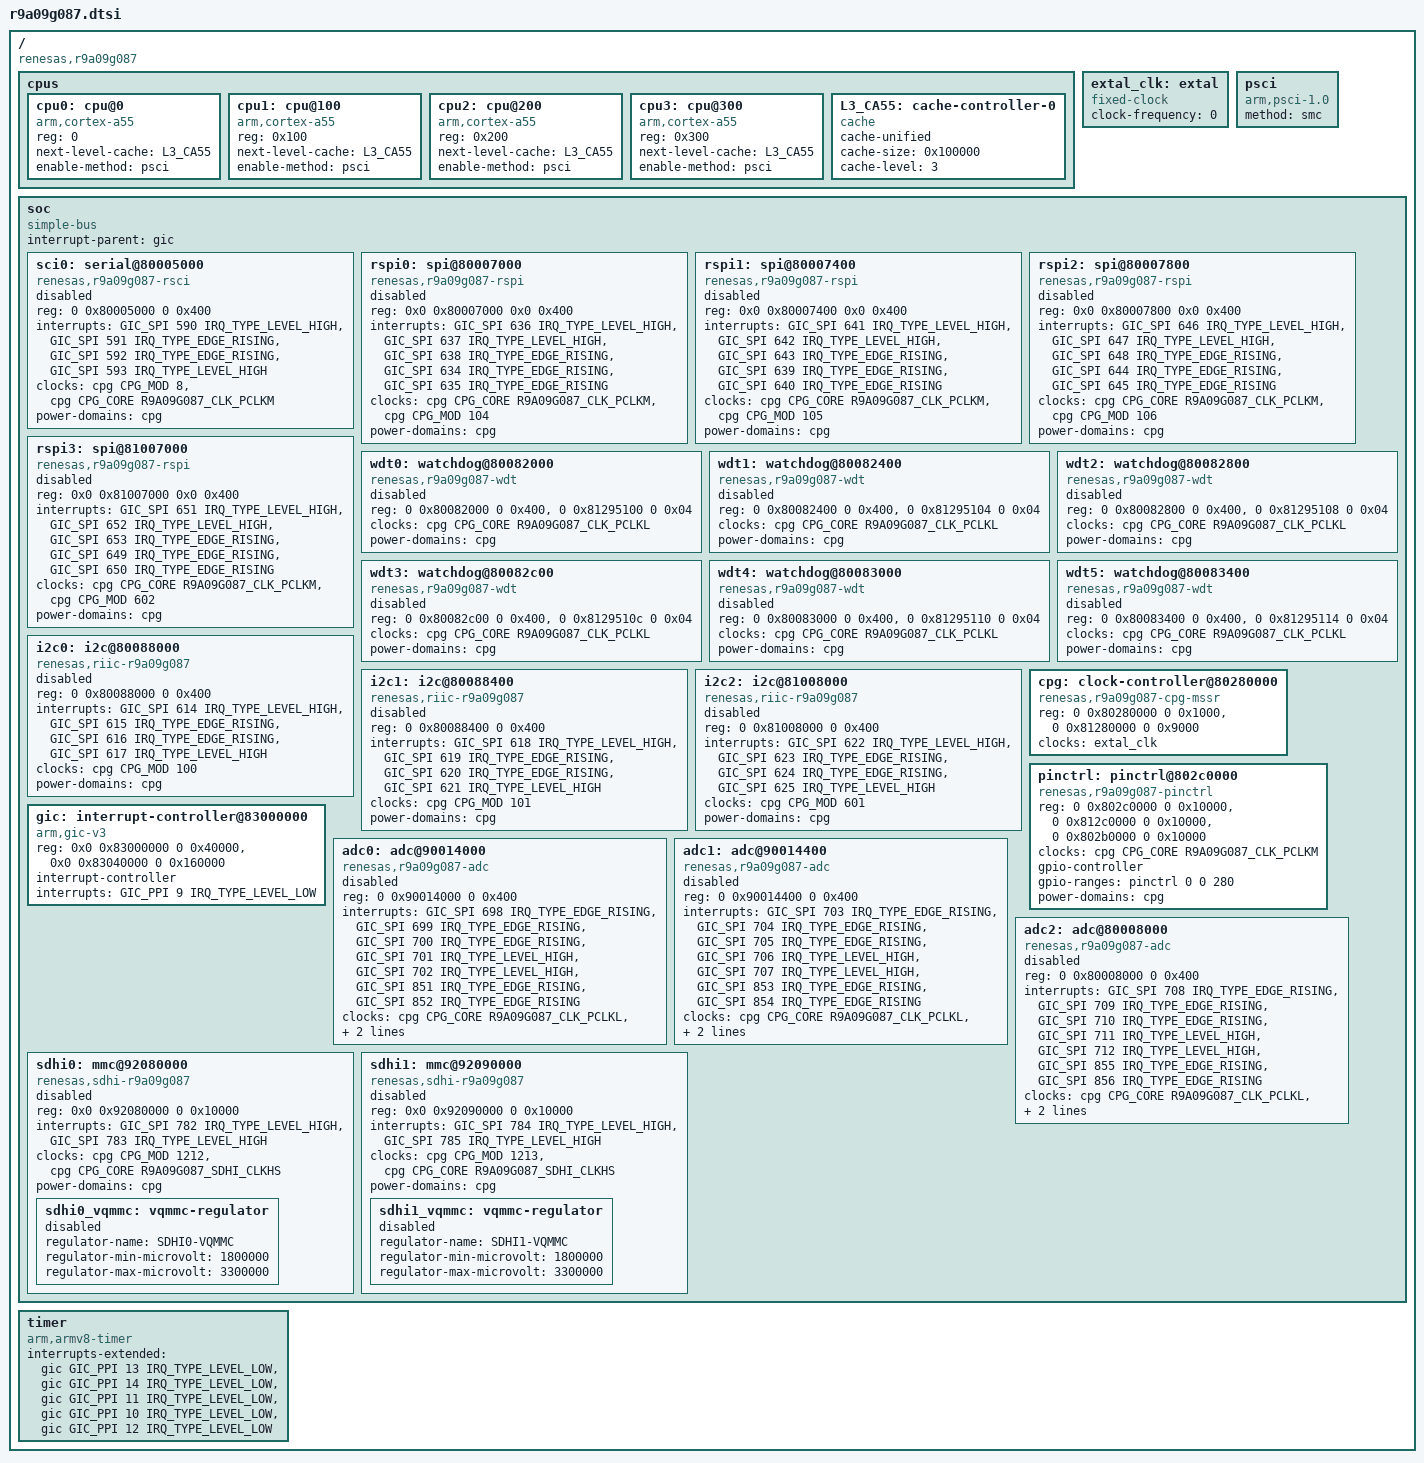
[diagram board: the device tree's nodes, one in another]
// SPDX-License-Identifier: (GPL-2.0-only OR BSD-2-Clause)
/*
 * Device Tree Source for the RZ/N2H SoC
 *
 * Copyright (C) 2025 Renesas Electronics Corp.
 */

#include <dt-bindings/clock/renesas,r9a09g087-cpg-mssr.h>
#include <dt-bindings/interrupt-controller/arm-gic.h>

/ {
	compatible = "renesas,r9a09g087";
	#address-cells = <2>;
	#size-cells = <2>;

	cpus {
		#address-cells = <1>;
		#size-cells = <0>;

		cpu0: cpu@0 {
			compatible = "arm,cortex-a55";
			reg = <0>;
			device_type = "cpu";
			next-level-cache = <&L3_CA55>;
			enable-method = "psci";
		};

		cpu1: cpu@100 {
			compatible = "arm,cortex-a55";
			reg = <0x100>;
			device_type = "cpu";
			next-level-cache = <&L3_CA55>;
			enable-method = "psci";
		};

		cpu2: cpu@200 {
			compatible = "arm,cortex-a55";
			reg = <0x200>;
			device_type = "cpu";
			next-level-cache = <&L3_CA55>;
			enable-method = "psci";
		};

		cpu3: cpu@300 {
			compatible = "arm,cortex-a55";
			reg = <0x300>;
			device_type = "cpu";
			next-level-cache = <&L3_CA55>;
			enable-method = "psci";
		};

		L3_CA55: cache-controller-0 {
			compatible = "cache";
			cache-unified;
			cache-size = <0x100000>;
			cache-level = <3>;
		};
	};

	extal_clk: extal {
		compatible = "fixed-clock";
		#clock-cells = <0>;
		/* This value must be overridden by the board */
		clock-frequency = <0>;
	};

	psci {
		compatible = "arm,psci-1.0", "arm,psci-0.2";
		method = "smc";
	};

	soc: soc {
		compatible = "simple-bus";
		interrupt-parent = <&gic>;
		#address-cells = <2>;
		#size-cells = <2>;
		ranges;

		sci0: serial@80005000 {
			compatible = "renesas,r9a09g087-rsci", "renesas,r9a09g077-rsci";
			reg = <0 0x80005000 0 0x400>;
			interrupts = <GIC_SPI 590 IRQ_TYPE_LEVEL_HIGH>,
				     <GIC_SPI 591 IRQ_TYPE_EDGE_RISING>,
				     <GIC_SPI 592 IRQ_TYPE_EDGE_RISING>,
				     <GIC_SPI 593 IRQ_TYPE_LEVEL_HIGH>;
			interrupt-names = "eri", "rxi", "txi", "tei";
			clocks = <&cpg CPG_MOD 8>, <&cpg CPG_CORE R9A09G087_CLK_PCLKM>;
			clock-names = "operation", "bus";
			power-domains = <&cpg>;
			status = "disabled";
		};

		rspi0: spi@80007000 {
			compatible = "renesas,r9a09g087-rspi", "renesas,r9a09g077-rspi";
			reg = <0x0 0x80007000 0x0 0x400>;
			interrupts = <GIC_SPI 636 IRQ_TYPE_LEVEL_HIGH>,
				     <GIC_SPI 637 IRQ_TYPE_LEVEL_HIGH>,
				     <GIC_SPI 638 IRQ_TYPE_EDGE_RISING>,
				     <GIC_SPI 634 IRQ_TYPE_EDGE_RISING>,
				     <GIC_SPI 635 IRQ_TYPE_EDGE_RISING>;
			interrupt-names = "idle", "error", "end", "rx", "tx";
			clocks = <&cpg CPG_CORE R9A09G087_CLK_PCLKM>,
				 <&cpg CPG_MOD 104>;
			clock-names = "pclk", "pclkspi";
			power-domains = <&cpg>;
			#address-cells = <1>;
			#size-cells = <0>;
			status = "disabled";
		};

		rspi1: spi@80007400 {
			compatible = "renesas,r9a09g087-rspi", "renesas,r9a09g077-rspi";
			reg = <0x0 0x80007400 0x0 0x400>;
			interrupts = <GIC_SPI 641 IRQ_TYPE_LEVEL_HIGH>,
				     <GIC_SPI 642 IRQ_TYPE_LEVEL_HIGH>,
				     <GIC_SPI 643 IRQ_TYPE_EDGE_RISING>,
				     <GIC_SPI 639 IRQ_TYPE_EDGE_RISING>,
				     <GIC_SPI 640 IRQ_TYPE_EDGE_RISING>;
			interrupt-names = "idle", "error", "end", "rx", "tx";
			clocks = <&cpg CPG_CORE R9A09G087_CLK_PCLKM>,
				 <&cpg CPG_MOD 105>;
			clock-names = "pclk", "pclkspi";
			power-domains = <&cpg>;
			#address-cells = <1>;
			#size-cells = <0>;
			status = "disabled";
		};

		rspi2: spi@80007800 {
			compatible = "renesas,r9a09g087-rspi", "renesas,r9a09g077-rspi";
			reg = <0x0 0x80007800 0x0 0x400>;
			interrupts = <GIC_SPI 646 IRQ_TYPE_LEVEL_HIGH>,
				     <GIC_SPI 647 IRQ_TYPE_LEVEL_HIGH>,
				     <GIC_SPI 648 IRQ_TYPE_EDGE_RISING>,
				     <GIC_SPI 644 IRQ_TYPE_EDGE_RISING>,
				     <GIC_SPI 645 IRQ_TYPE_EDGE_RISING>;
			interrupt-names = "idle", "error", "end", "rx", "tx";
			clocks = <&cpg CPG_CORE R9A09G087_CLK_PCLKM>,
				 <&cpg CPG_MOD 106>;
			clock-names = "pclk", "pclkspi";
			power-domains = <&cpg>;
			#address-cells = <1>;
			#size-cells = <0>;
			status = "disabled";
		};

		rspi3: spi@81007000 {
			compatible = "renesas,r9a09g087-rspi", "renesas,r9a09g077-rspi";
			reg = <0x0 0x81007000 0x0 0x400>;
			interrupts = <GIC_SPI 651 IRQ_TYPE_LEVEL_HIGH>,
				     <GIC_SPI 652 IRQ_TYPE_LEVEL_HIGH>,
				     <GIC_SPI 653 IRQ_TYPE_EDGE_RISING>,
				     <GIC_SPI 649 IRQ_TYPE_EDGE_RISING>,
				     <GIC_SPI 650 IRQ_TYPE_EDGE_RISING>;
			interrupt-names = "idle", "error", "end", "rx", "tx";
			clocks = <&cpg CPG_CORE R9A09G087_CLK_PCLKM>,
				 <&cpg CPG_MOD 602>;
			clock-names = "pclk", "pclkspi";
			power-domains = <&cpg>;
			#address-cells = <1>;
			#size-cells = <0>;
			status = "disabled";
		};

		wdt0: watchdog@80082000 {
			compatible = "renesas,r9a09g087-wdt", "renesas,r9a09g077-wdt";
			reg = <0 0x80082000 0 0x400>,
			      <0 0x81295100 0 0x04>;
			clocks = <&cpg CPG_CORE R9A09G087_CLK_PCLKL>;
			clock-names = "pclk";
			power-domains = <&cpg>;
			status = "disabled";
		};

		wdt1: watchdog@80082400 {
			compatible = "renesas,r9a09g087-wdt", "renesas,r9a09g077-wdt";
			reg = <0 0x80082400 0 0x400>,
			      <0 0x81295104 0 0x04>;
			clocks = <&cpg CPG_CORE R9A09G087_CLK_PCLKL>;
			clock-names = "pclk";
			power-domains = <&cpg>;
			status = "disabled";
		};

		wdt2: watchdog@80082800 {
			compatible = "renesas,r9a09g087-wdt", "renesas,r9a09g077-wdt";
			reg = <0 0x80082800 0 0x400>,
			      <0 0x81295108 0 0x04>;
			clocks = <&cpg CPG_CORE R9A09G087_CLK_PCLKL>;
			clock-names = "pclk";
			power-domains = <&cpg>;
			status = "disabled";
		};

		wdt3: watchdog@80082c00 {
			compatible = "renesas,r9a09g087-wdt", "renesas,r9a09g077-wdt";
			reg = <0 0x80082c00 0 0x400>,
			      <0 0x8129510c 0 0x04>;
			clocks = <&cpg CPG_CORE R9A09G087_CLK_PCLKL>;
			clock-names = "pclk";
			power-domains = <&cpg>;
			status = "disabled";
		};

		wdt4: watchdog@80083000 {
			compatible = "renesas,r9a09g087-wdt", "renesas,r9a09g077-wdt";
			reg = <0 0x80083000 0 0x400>,
			      <0 0x81295110 0 0x04>;
			clocks = <&cpg CPG_CORE R9A09G087_CLK_PCLKL>;
			clock-names = "pclk";
			power-domains = <&cpg>;
			status = "disabled";
		};

		wdt5: watchdog@80083400 {
			compatible = "renesas,r9a09g087-wdt", "renesas,r9a09g077-wdt";
			reg = <0 0x80083400 0 0x400>,
			      <0 0x81295114 0 0x04>;
			clocks = <&cpg CPG_CORE R9A09G087_CLK_PCLKL>;
			clock-names = "pclk";
			power-domains = <&cpg>;
			status = "disabled";
		};

		i2c0: i2c@80088000 {
			compatible = "renesas,riic-r9a09g087", "renesas,riic-r9a09g077";
			reg = <0 0x80088000 0 0x400>;
			interrupts = <GIC_SPI 614 IRQ_TYPE_LEVEL_HIGH>,
				     <GIC_SPI 615 IRQ_TYPE_EDGE_RISING>,
				     <GIC_SPI 616 IRQ_TYPE_EDGE_RISING>,
				     <GIC_SPI 617 IRQ_TYPE_LEVEL_HIGH>;
			interrupt-names = "eei", "rxi", "txi", "tei";
			clocks = <&cpg CPG_MOD 100>;
			power-domains = <&cpg>;
			#address-cells = <1>;
			#size-cells = <0>;
			status = "disabled";
		};

		i2c1: i2c@80088400 {
			compatible = "renesas,riic-r9a09g087", "renesas,riic-r9a09g077";
			reg = <0 0x80088400 0 0x400>;
			interrupts = <GIC_SPI 618 IRQ_TYPE_LEVEL_HIGH>,
				     <GIC_SPI 619 IRQ_TYPE_EDGE_RISING>,
				     <GIC_SPI 620 IRQ_TYPE_EDGE_RISING>,
				     <GIC_SPI 621 IRQ_TYPE_LEVEL_HIGH>;
			interrupt-names = "eei", "rxi", "txi", "tei";
			clocks = <&cpg CPG_MOD 101>;
			power-domains = <&cpg>;
			#address-cells = <1>;
			#size-cells = <0>;
			status = "disabled";
		};

		i2c2: i2c@81008000 {
			compatible = "renesas,riic-r9a09g087", "renesas,riic-r9a09g077";
			reg = <0 0x81008000 0 0x400>;
			interrupts = <GIC_SPI 622 IRQ_TYPE_LEVEL_HIGH>,
				     <GIC_SPI 623 IRQ_TYPE_EDGE_RISING>,
				     <GIC_SPI 624 IRQ_TYPE_EDGE_RISING>,
				     <GIC_SPI 625 IRQ_TYPE_LEVEL_HIGH>;
			interrupt-names = "eei", "rxi", "txi", "tei";
			clocks = <&cpg CPG_MOD 601>;
			power-domains = <&cpg>;
			#address-cells = <1>;
			#size-cells = <0>;
			status = "disabled";
		};

		cpg: clock-controller@80280000 {
			compatible = "renesas,r9a09g087-cpg-mssr";
			reg = <0 0x80280000 0 0x1000>,
			      <0 0x81280000 0 0x9000>;
			clocks = <&extal_clk>;
			clock-names = "extal";
			#clock-cells = <2>;
			#reset-cells = <1>;
			#power-domain-cells = <0>;
		};

		pinctrl: pinctrl@802c0000 {
			compatible = "renesas,r9a09g087-pinctrl";
			reg = <0 0x802c0000 0 0x10000>,
			      <0 0x812c0000 0 0x10000>,
			      <0 0x802b0000 0 0x10000>;
			reg-names = "nsr", "srs", "srn";
			clocks = <&cpg CPG_CORE R9A09G087_CLK_PCLKM>;
			gpio-controller;
			#gpio-cells = <2>;
			gpio-ranges = <&pinctrl 0 0 280>;
			power-domains = <&cpg>;
		};

		gic: interrupt-controller@83000000 {
			compatible = "arm,gic-v3";
			reg = <0x0 0x83000000 0 0x40000>,
			      <0x0 0x83040000 0 0x160000>;
			#interrupt-cells = <3>;
			#address-cells = <0>;
			interrupt-controller;
			interrupts = <GIC_PPI 9 IRQ_TYPE_LEVEL_LOW>;
		};

		adc0: adc@90014000 {
			compatible = "renesas,r9a09g087-adc", "renesas,r9a09g077-adc";
			reg = <0 0x90014000 0 0x400>;
			interrupts = <GIC_SPI 698 IRQ_TYPE_EDGE_RISING>,
				     <GIC_SPI 699 IRQ_TYPE_EDGE_RISING>,
				     <GIC_SPI 700 IRQ_TYPE_EDGE_RISING>,
				     <GIC_SPI 701 IRQ_TYPE_LEVEL_HIGH>,
				     <GIC_SPI 702 IRQ_TYPE_LEVEL_HIGH>,
				     <GIC_SPI 851 IRQ_TYPE_EDGE_RISING>,
				     <GIC_SPI 852 IRQ_TYPE_EDGE_RISING>;
			interrupt-names = "adi", "gbadi", "gcadi",
					  "cmpai", "cmpbi", "wcmpm", "wcmpum";
			clocks = <&cpg CPG_CORE R9A09G087_CLK_PCLKL>,
				 <&cpg CPG_MOD 206>;
			clock-names = "adclk", "pclk";
			power-domains = <&cpg>;
			#address-cells = <1>;
			#size-cells = <0>;
			#io-channel-cells = <1>;
			status = "disabled";
		};

		adc1: adc@90014400 {
			compatible = "renesas,r9a09g087-adc", "renesas,r9a09g077-adc";
			reg = <0 0x90014400 0 0x400>;
			interrupts = <GIC_SPI 703 IRQ_TYPE_EDGE_RISING>,
				     <GIC_SPI 704 IRQ_TYPE_EDGE_RISING>,
				     <GIC_SPI 705 IRQ_TYPE_EDGE_RISING>,
				     <GIC_SPI 706 IRQ_TYPE_LEVEL_HIGH>,
				     <GIC_SPI 707 IRQ_TYPE_LEVEL_HIGH>,
				     <GIC_SPI 853 IRQ_TYPE_EDGE_RISING>,
				     <GIC_SPI 854 IRQ_TYPE_EDGE_RISING>;
			interrupt-names = "adi", "gbadi", "gcadi",
					  "cmpai", "cmpbi", "wcmpm", "wcmpum";
			clocks = <&cpg CPG_CORE R9A09G087_CLK_PCLKL>,
				 <&cpg CPG_MOD 207>;
			clock-names = "adclk", "pclk";
			power-domains = <&cpg>;
			#address-cells = <1>;
			#size-cells = <0>;
			#io-channel-cells = <1>;
			status = "disabled";
		};

		adc2: adc@80008000 {
			compatible = "renesas,r9a09g087-adc", "renesas,r9a09g077-adc";
			reg = <0 0x80008000 0 0x400>;
			interrupts = <GIC_SPI 708 IRQ_TYPE_EDGE_RISING>,
				     <GIC_SPI 709 IRQ_TYPE_EDGE_RISING>,
				     <GIC_SPI 710 IRQ_TYPE_EDGE_RISING>,
				     <GIC_SPI 711 IRQ_TYPE_LEVEL_HIGH>,
				     <GIC_SPI 712 IRQ_TYPE_LEVEL_HIGH>,
				     <GIC_SPI 855 IRQ_TYPE_EDGE_RISING>,
				     <GIC_SPI 856 IRQ_TYPE_EDGE_RISING>;
			interrupt-names = "adi", "gbadi", "gcadi",
					  "cmpai", "cmpbi", "wcmpm", "wcmpum";
			clocks = <&cpg CPG_CORE R9A09G087_CLK_PCLKL>,
				 <&cpg CPG_MOD 225>;
			clock-names = "adclk", "pclk";
			power-domains = <&cpg>;
			#address-cells = <1>;
			#size-cells = <0>;
			#io-channel-cells = <1>;
			status = "disabled";
		};

		sdhi0: mmc@92080000  {
			compatible = "renesas,sdhi-r9a09g087",
				     "renesas,sdhi-r9a09g057";
			reg = <0x0 0x92080000 0 0x10000>;
			interrupts = <GIC_SPI 782 IRQ_TYPE_LEVEL_HIGH>,
				     <GIC_SPI 783 IRQ_TYPE_LEVEL_HIGH>;
			clocks = <&cpg CPG_MOD 1212>,
				 <&cpg CPG_CORE R9A09G087_SDHI_CLKHS>;
			clock-names = "aclk", "clkh";
			power-domains = <&cpg>;
			status = "disabled";

			sdhi0_vqmmc: vqmmc-regulator {
				regulator-name = "SDHI0-VQMMC";
				regulator-min-microvolt = <1800000>;
				regulator-max-microvolt = <3300000>;
				status = "disabled";
			};
		};

		sdhi1: mmc@92090000 {
			compatible = "renesas,sdhi-r9a09g087",
				     "renesas,sdhi-r9a09g057";
			reg = <0x0 0x92090000 0 0x10000>;
			interrupts = <GIC_SPI 784 IRQ_TYPE_LEVEL_HIGH>,
				     <GIC_SPI 785 IRQ_TYPE_LEVEL_HIGH>;
			clocks = <&cpg CPG_MOD 1213>,
				 <&cpg CPG_CORE R9A09G087_SDHI_CLKHS>;
			clock-names = "aclk", "clkh";
			power-domains = <&cpg>;
			status = "disabled";

			sdhi1_vqmmc: vqmmc-regulator {
				regulator-name = "SDHI1-VQMMC";
				regulator-min-microvolt = <1800000>;
				regulator-max-microvolt = <3300000>;
				status = "disabled";
			};
		};
	};

	timer {
		compatible = "arm,armv8-timer";
		interrupts-extended = <&gic GIC_PPI 13 IRQ_TYPE_LEVEL_LOW>,
				      <&gic GIC_PPI 14 IRQ_TYPE_LEVEL_LOW>,
				      <&gic GIC_PPI 11 IRQ_TYPE_LEVEL_LOW>,
				      <&gic GIC_PPI 10 IRQ_TYPE_LEVEL_LOW>,
				      <&gic GIC_PPI 12 IRQ_TYPE_LEVEL_LOW>;
		interrupt-names = "sec-phys", "phys", "virt", "hyp-phys", "hyp-virt";
	};
};
